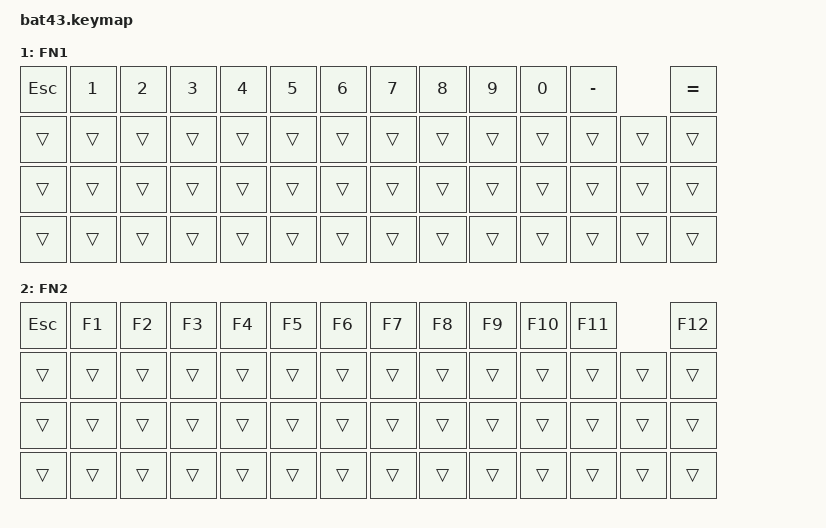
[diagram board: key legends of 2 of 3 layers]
#include <behaviors.dtsi>
#include <dt-bindings/zmk/keys.h>
#include <dt-bindings/zmk/bt.h>
#include <dt-bindings/zmk/outputs.h>

/ {
    keymap {
        compatible = "zmk,keymap";

        BASE {
            bindings = <
                &kp TAB &kp Q &kp W &kp E &kp R &kp T &kp Y &kp U &kp I &kp O &kp P &kp LBKT &kp RBKT
                &kp CAPS &kp A &kp S &kp D &kp F &kp G &kp H &kp J &kp K &kp L &kp SEMI &kp SQT &kp ENTER
                &kp LSHFT &kp Z &kp X &kp C &kp V &kp B &kp N &kp M &kp COMMA &kp DOT &kp SLASH &kp BSPC &kp ESC &kp DEL
                &mo FN1 &mo FN2 &kp SPACE &kp LALT &kp LCTRL &trans &trans &trans &trans &trans &trans &trans &trans
            >;
        };

        FN1 {
            bindings = <
                &kp ESC &kp N1 &kp N2 &kp N3 &kp N4 &kp N5 &kp N6 &kp N7 &kp N8 &kp N9 &kp N0 &kp MINUS &kp EQUAL
                &trans &trans &trans &trans &trans &trans &trans &trans &trans &trans &trans &trans &trans &trans
                &trans &trans &trans &trans &trans &trans &trans &trans &trans &trans &trans &trans &trans &trans
                &trans &trans &trans &trans &trans &trans &trans &trans &trans &trans &trans &trans &trans &trans
            >;
        };

        FN2 {
            bindings = <
                &kp ESC &kp F1 &kp F2 &kp F3 &kp F4 &kp F5 &kp F6 &kp F7 &kp F8 &kp F9 &kp F10 &kp F11 &kp F12
                &trans &trans &trans &trans &trans &trans &trans &trans &trans &trans &trans &trans &trans &trans
                &trans &trans &trans &trans &trans &trans &trans &trans &trans &trans &trans &trans &trans &trans
                &trans &trans &trans &trans &trans &trans &trans &trans &trans &trans &trans &trans &trans &trans
            >;
        };
    };
};
